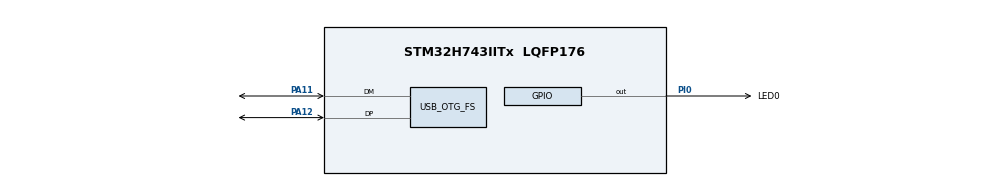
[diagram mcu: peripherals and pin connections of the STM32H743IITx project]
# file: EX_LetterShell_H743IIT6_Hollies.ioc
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ADC3.Channel-0\#ChannelRegularConversion=ADC_CHANNEL_TEMPSENSOR
ADC3.ClockPrescalerADC3=ADC_CLOCK_ASYNC_DIV4
ADC3.NbrOfConversionFlag=1
ADC3.OffsetNumber-0\#ChannelRegularConversion=ADC_OFFSET_NONE
ADC3.OffsetSignedSaturation-0\#ChannelRegularConversion=DISABLE
ADC3.Overrun=ADC_OVR_DATA_OVERWRITTEN
ADC3.OversamplingMode=ENABLE
ADC3.Rank-0\#ChannelRegularConversion=1
ADC3.Ratio=16
ADC3.RightBitShift=ADC_RIGHTBITSHIFT_4
ADC3.SamplingTime-0\#ChannelRegularConversion=ADC_SAMPLETIME_810CYCLES_5
CORTEX_M7.AccessPermission_Spec=MPU_REGION_FULL_ACCESS
CORTEX_M7.BaseAddress_Spec=0x24000000
CORTEX_M7.CPU_DCache=Enabled
CORTEX_M7.CPU_ICache=Enabled
CORTEX_M7.DisableExec_Spec=MPU_INSTRUCTION_ACCESS_ENABLE
CORTEX_M7.IsBufferable_Spec=MPU_ACCESS_BUFFERABLE
CORTEX_M7.IsCacheable_Spec=MPU_ACCESS_CACHEABLE
CORTEX_M7.IsShareable_Spec=MPU_ACCESS_NOT_SHAREABLE
CORTEX_M7.Size_Spec=MPU_REGION_SIZE_512KB
CORTEX_M7.SubRegionDisable_Spec=0x0
CORTEX_M7.TypeExtField_Spec=MPU_TEX_LEVEL1
CORTEX_M7.default_mode_Activation=1
FREERTOS.Tasks01=defaultTask,24,256,StartDefaultTask,As weak,NULL,Dynamic,NULL,NULL;letterShellTask,8,1024,shellTask,As weak,&shell,Dynamic,NULL,NULL;chipTemperature,24,512,StartChipTemperatureTask,As weak,NULL,Dynamic,NULL,NULL
Mcu.Family=STM32H7
Mcu.Name=STM32H743IITx
Mcu.Package=LQFP176
NVIC.OTG_FS_IRQn=true\:5\:0\:false\:false\:true\:true\:false\:true\:true
NVIC.PriorityGroup=NVIC_PRIORITYGROUP_4
NVIC.TIM6_DAC_IRQn=true\:15\:0\:false\:false\:true\:false\:false\:true\:true
NVIC.TimeBase=TIM6_DAC_IRQn
NVIC.TimeBaseIP=TIM6
PA11.Mode=Device_Only
PA11.Signal=USB_OTG_FS_DM
PA12.Mode=Device_Only
PA12.Signal=USB_OTG_FS_DP
PA13\ (JTMS/SWDIO).Mode=Serial_Wire
PA13\ (JTMS/SWDIO).Signal=DEBUG_JTMS-SWDIO
PA14\ (JTCK/SWCLK).Mode=Serial_Wire
PA14\ (JTCK/SWCLK).Signal=DEBUG_JTCK-SWCLK
PC14-OSC32_IN\ (OSC32_IN).Mode=LSE-External-Oscillator
PC14-OSC32_IN\ (OSC32_IN).Signal=RCC_OSC32_IN
PC15-OSC32_OUT\ (OSC32_OUT).Mode=LSE-External-Oscillator
PC15-OSC32_OUT\ (OSC32_OUT).Signal=RCC_OSC32_OUT
PH0-OSC_IN\ (PH0).Mode=HSE-External-Oscillator
PH0-OSC_IN\ (PH0).Signal=RCC_OSC_IN
PH1-OSC_OUT\ (PH1).Mode=HSE-External-Oscillator
PH1-OSC_OUT\ (PH1).Signal=RCC_OSC_OUT
PI0.GPIO_Label=LED0
PI0.Signal=GPIO_Output
ProjectManager.HeapSize=0x2000
ProjectManager.StackSize=0x4000
ProjectManager.TargetToolchain=CMake
RCC.ADCFreq_Value=72000000
RCC.APB1Freq_Value=120000000
RCC.APB2Freq_Value=120000000
RCC.APB3Freq_Value=120000000
RCC.APB4Freq_Value=120000000
RCC.CortexFreq_Value=480000000
RCC.D1PPRE=RCC_APB3_DIV2
RCC.D2PPRE1=RCC_APB1_DIV2
RCC.D2PPRE2=RCC_APB2_DIV2
RCC.D3PPRE=RCC_APB4_DIV2
RCC.DIVM1=5
RCC.DIVM2=25
RCC.DIVM3=25
RCC.DIVN1=192
RCC.DIVN2=504
RCC.DIVN3=300
RCC.DIVP2=7
RCC.DIVQ1=20
RCC.HCLKFreq_Value=240000000
RCC.HPRE=RCC_HCLK_DIV2
RCC.PLLSourceVirtual=RCC_PLLSOURCE_HSE
RCC.SYSCLKFreq_VALUE=480000000
RCC.SYSCLKSource=RCC_SYSCLKSOURCE_PLLCLK
RCC.USBFreq_Value=48000000
USB_DEVICE.CLASS_NAME_FS=CDC
USB_DEVICE.PRODUCT_STRING_CDC_FS=Tian Shu A
USB_DEVICE.VirtualMode-CDC_FS=Cdc
USB_DEVICE.VirtualModeFS=Cdc_FS
USB_OTG_FS.VirtualMode=Device_Only
VP_ADC3_TempSens_Input.Mode=IN-TempSens
VP_FREERTOS_VS_CMSIS_V2.Mode=CMSIS_V2
VP_MEMORYMAP_VS_MEMORYMAP.Mode=CurAppReg
VP_SYS_VS_tim6.Mode=TIM6
VP_USB_DEVICE_VS_USB_DEVICE_CDC_FS.Mode=CDC_FS
board=custom

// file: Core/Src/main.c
/* USER CODE BEGIN Header */
/**
  ******************************************************************************
  * @file           : main.c
  * @brief          : Main program body
  ******************************************************************************
  * @attention
  *
  * Copyright (c) 2024 STMicroelectronics.
  * All rights reserved.
  *
  * This software is licensed under terms that can be found in the LICENSE file
  * in the root directory of this software component.
  * If no LICENSE file comes with this software, it is provided AS-IS.
  *
  ******************************************************************************
  */
/* USER CODE END Header */
#include "main.h"
#include "cmsis_os.h"
#include "adc.h"
#include "memorymap.h"
#include "usb_device.h"
#include "gpio.h"

void SystemClock_Config(void);
static void MPU_Config(void);
void MX_FREERTOS_Init(void);

int main(void)
{

  /* MPU Configuration--------------------------------------------------------*/
  MPU_Config();

  /* Enable the CPU Cache */

  /* Enable I-Cache---------------------------------------------------------*/
  SCB_EnableICache();

  /* Enable D-Cache---------------------------------------------------------*/
  SCB_EnableDCache();

  /* MCU Configuration--------------------------------------------------------*/

  /* Reset of all peripherals, Initializes the Flash interface and the Systick. */
  HAL_Init();

  /* Configure the system clock */
  SystemClock_Config();

  /* Initialize all configured peripherals */
  MX_GPIO_Init();
  MX_ADC3_Init();

  /* Init scheduler */
  osKernelInitialize();

  /* Call init function for freertos objects (in cmsis_os2.c) */
  MX_FREERTOS_Init();

  /* Start scheduler */
  osKernelStart();

  /* We should never get here as control is now taken by the scheduler */

  /* Infinite loop */
  while (1)
  {

  }
}

void SystemClock_Config(void)
{
  RCC_OscInitTypeDef RCC_OscInitStruct = {0};
  RCC_ClkInitTypeDef RCC_ClkInitStruct = {0};

  /** Supply configuration update enable
  */
  HAL_PWREx_ConfigSupply(PWR_LDO_SUPPLY);

  /** Configure the main internal regulator output voltage
  */
  __HAL_PWR_VOLTAGESCALING_CONFIG(PWR_REGULATOR_VOLTAGE_SCALE1);

  while(!__HAL_PWR_GET_FLAG(PWR_FLAG_VOSRDY)) {}

  __HAL_RCC_SYSCFG_CLK_ENABLE();
  __HAL_PWR_VOLTAGESCALING_CONFIG(PWR_REGULATOR_VOLTAGE_SCALE0);

  while(!__HAL_PWR_GET_FLAG(PWR_FLAG_VOSRDY)) {}

  /** Initializes the RCC Oscillators according to the specified parameters
  * in the RCC_OscInitTypeDef structure.
  */
  RCC_OscInitStruct.OscillatorType = RCC_OSCILLATORTYPE_HSE;
  RCC_OscInitStruct.HSEState = RCC_HSE_ON;
  RCC_OscInitStruct.PLL.PLLState = RCC_PLL_ON;
  RCC_OscInitStruct.PLL.PLLSource = RCC_PLLSOURCE_HSE;
  RCC_OscInitStruct.PLL.PLLM = 5;
  RCC_OscInitStruct.PLL.PLLN = 192;
  RCC_OscInitStruct.PLL.PLLP = 2;
  RCC_OscInitStruct.PLL.PLLQ = 20;
  RCC_OscInitStruct.PLL.PLLR = 2;
  RCC_OscInitStruct.PLL.PLLRGE = RCC_PLL1VCIRANGE_2;
  RCC_OscInitStruct.PLL.PLLVCOSEL = RCC_PLL1VCOWIDE;
  RCC_OscInitStruct.PLL.PLLFRACN = 0;
  if (HAL_RCC_OscConfig(&RCC_OscInitStruct) != HAL_OK)
  {
    Error_Handler();
  }

  /** Initializes the CPU, AHB and APB buses clocks
  */
  RCC_ClkInitStruct.ClockType = RCC_CLOCKTYPE_HCLK|RCC_CLOCKTYPE_SYSCLK
                              |RCC_CLOCKTYPE_PCLK1|RCC_CLOCKTYPE_PCLK2
                              |RCC_CLOCKTYPE_D3PCLK1|RCC_CLOCKTYPE_D1PCLK1;
  RCC_ClkInitStruct.SYSCLKSource = RCC_SYSCLKSOURCE_PLLCLK;
  RCC_ClkInitStruct.SYSCLKDivider = RCC_SYSCLK_DIV1;
  RCC_ClkInitStruct.AHBCLKDivider = RCC_HCLK_DIV2;
  RCC_ClkInitStruct.APB3CLKDivider = RCC_APB3_DIV2;
  RCC_ClkInitStruct.APB1CLKDivider = RCC_APB1_DIV2;
  RCC_ClkInitStruct.APB2CLKDivider = RCC_APB2_DIV2;
  RCC_ClkInitStruct.APB4CLKDivider = RCC_APB4_DIV2;

  if (HAL_RCC_ClockConfig(&RCC_ClkInitStruct, FLASH_LATENCY_4) != HAL_OK)
  {
    Error_Handler();
  }
}

 /* MPU Configuration */

void MPU_Config(void)
{
  MPU_Region_InitTypeDef MPU_InitStruct = {0};

  /* Disables the MPU */
  HAL_MPU_Disable();

  /** Initializes and configures the Region and the memory to be protected
  */
  MPU_InitStruct.Enable = MPU_REGION_ENABLE;
  MPU_InitStruct.Number = MPU_REGION_NUMBER0;
  MPU_InitStruct.BaseAddress = 0x24000000;
  MPU_InitStruct.Size = MPU_REGION_SIZE_512KB;
  MPU_InitStruct.SubRegionDisable = 0x0;
  MPU_InitStruct.TypeExtField = MPU_TEX_LEVEL1;
  MPU_InitStruct.AccessPermission = MPU_REGION_FULL_ACCESS;
  MPU_InitStruct.DisableExec = MPU_INSTRUCTION_ACCESS_ENABLE;
  MPU_InitStruct.IsShareable = MPU_ACCESS_NOT_SHAREABLE;
  MPU_InitStruct.IsCacheable = MPU_ACCESS_CACHEABLE;
  MPU_InitStruct.IsBufferable = MPU_ACCESS_BUFFERABLE;

  HAL_MPU_ConfigRegion(&MPU_InitStruct);
  /* Enables the MPU */
  HAL_MPU_Enable(MPU_PRIVILEGED_DEFAULT);

}

void HAL_TIM_PeriodElapsedCallback(TIM_HandleTypeDef *htim)
{
  if (htim->Instance == TIM6) {
    HAL_IncTick();
  }
}

void Error_Handler(void)
{
  __disable_irq();
  while (1)
  {
  }
}

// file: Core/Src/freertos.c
/* USER CODE BEGIN Header */
/**
 ******************************************************************************
 * File Name          : freertos.c
 * Description        : Code for freertos applications
 ******************************************************************************
 * @attention
 *
 * Copyright (c) 2024 STMicroelectronics.
 * All rights reserved.
 *
 * This software is licensed under terms that can be found in the LICENSE file
 * in the root directory of this software component.
 * If no LICENSE file comes with this software, it is provided AS-IS.
 *
 ******************************************************************************
 */
/* USER CODE END Header */

#include "FreeRTOS.h"
#include "task.h"
#include "main.h"
#include "cmsis_os.h"

/* USER CODE BEGIN Includes */
#include "user_task.h"
#include "shell.h"
#include "user_shell.h"
/* USER CODE END Includes */

/* Definitions for defaultTask */
osThreadId_t defaultTaskHandle;
const osThreadAttr_t defaultTask_attributes = {
    .name = "defaultTask",
    .stack_size = 256 * 4,
    .priority = (osPriority_t)osPriorityNormal,
};
/* Definitions for letterShellTask */
osThreadId_t letterShellTaskHandle;
const osThreadAttr_t letterShellTask_attributes = {
    .name = "letterShellTask",
    .stack_size = 1024 * 4,
    .priority = (osPriority_t)osPriorityLow,
};
/* Definitions for chipTemperature */
osThreadId_t chipTemperatureHandle;
const osThreadAttr_t chipTemperature_attributes = {
    .name = "chipTemperature",
    .stack_size = 512 * 4,
    .priority = (osPriority_t)osPriorityNormal,
};

void StartDefaultTask(void *argument);
void shellTask(void *argument);
void StartChipTemperatureTask(void *argument);

extern void MX_USB_DEVICE_Init(void);
void MX_FREERTOS_Init(void); /* (MISRA C 2004 rule 8.1) */

void MX_FREERTOS_Init(void)
{
  /* USER CODE BEGIN Init */
  MX_USB_DEVICE_Init();
  userShellInit();
  /* USER CODE END Init */

  /* Create the thread(s) */
  /* creation of defaultTask */
  defaultTaskHandle = osThreadNew(StartDefaultTask, NULL, &defaultTask_attributes);

  /* creation of letterShellTask */
  letterShellTaskHandle = osThreadNew(shellTask, (void *)&shell, &letterShellTask_attributes);

  /* creation of chipTemperature */
  chipTemperatureHandle = osThreadNew(StartChipTemperatureTask, NULL, &chipTemperature_attributes);

}

__weak void StartDefaultTask(void *argument)
{
  /* init code for USB_DEVICE */
  UNUSED(argument);
  MX_USB_DEVICE_Init();
  for (;;)
  {
    osDelay(1);
  }
}

__weak void shellTask(void *argument)
{
  /* USER CODE BEGIN shellTask */
  UNUSED(argument);
  /* Infinite loop */
  for (;;)
  {
    osDelay(1);
  }
  /* USER CODE END shellTask */
}

__weak void StartChipTemperatureTask(void *argument)
{
  /* USER CODE BEGIN StartChipTemperatureTask */
  UNUSED(argument);
  /* Infinite loop */
  for (;;)
  {
    osDelay(1);
  }
  /* USER CODE END StartChipTemperatureTask */
}
